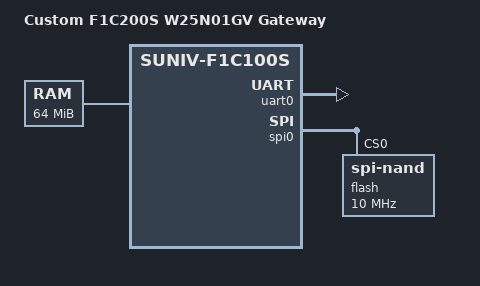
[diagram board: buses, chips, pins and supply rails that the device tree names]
// SPDX-License-Identifier: (GPL-2.0+ OR MIT)
/dts-v1/;
#include "suniv-f1c100s.dtsi"

/ {
    model = "Custom F1C200S W25N01GV Gateway";
    compatible = "custom,f1c200s-gateway", "allwinner,suniv-f1c100s";
    aliases { serial0 = &uart0; spi0 = &spi0; };
    chosen { stdout-path = "serial0:115200n8"; };
    memory@80000000 {
        device_type = "memory";
        reg = <0x80000000 0x04000000>;
    };
};
&uart0_pe_pins {
    bias-pull-up;
};

&uart0 {
    pinctrl-names = "default";
    pinctrl-0 = <&uart0_pe_pins>;
    status = "okay";
};
&spi0 {
    pinctrl-names = "default";
    pinctrl-0 = <&spi0_pc_pins>;
    status = "okay";
    flash@0 {
        compatible = "spi-nand";
        reg = <0>;
        spi-max-frequency = <10000000>;
        #include "gateway-nand-partitions.dtsi"
    };
};
&mmc0 { status = "disabled"; };
&usb_otg { status = "disabled"; };
&usbphy { status = "disabled"; };
